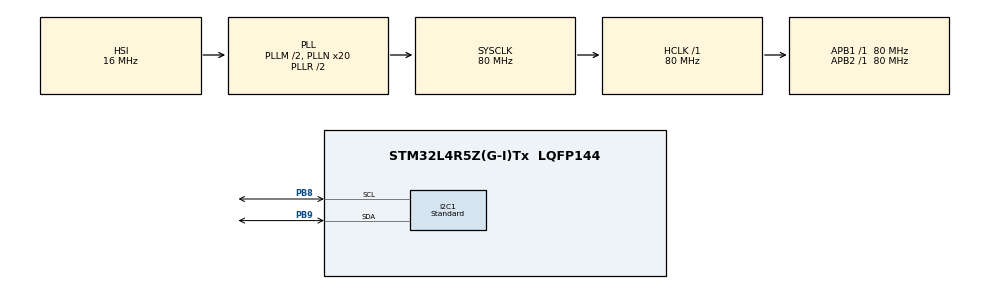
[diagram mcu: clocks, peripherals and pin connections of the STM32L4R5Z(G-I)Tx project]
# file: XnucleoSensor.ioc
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FREERTOS.Tasks01=defaultTask,0,1000,StartDefaultTask,Default,NULL,Dynamic,NULL,NULL
FREERTOS.configTOTAL_HEAP_SIZE=6000
I2C1.I2C_Speed_Mode=I2C_Standard
I2C1.Timing=0x10909CEC
Mcu.Family=STM32L4
Mcu.Name=STM32L4R5Z(G-I)Tx
Mcu.Package=LQFP144
NVIC.PriorityGroup=NVIC_PRIORITYGROUP_4
NVIC.TIM1_UP_TIM16_IRQn=true\:0\:0\:false\:false\:true\:false\:false\:true
NVIC.TimeBase=TIM1_UP_TIM16_IRQn
NVIC.TimeBaseIP=TIM1
PA13\ (JTMS/SWDIO).Mode=Serial_Wire
PA13\ (JTMS/SWDIO).Signal=SYS_JTMS-SWDIO
PA14\ (JTCK/SWCLK).Mode=Serial_Wire
PA14\ (JTCK/SWCLK).Signal=SYS_JTCK-SWCLK
PB8.Mode=I2C
PB8.Signal=I2C1_SCL
PB9.Mode=I2C
PB9.Signal=I2C1_SDA
PC14-OSC32_IN\ (PC14).Mode=LSE-External-Oscillator
PC14-OSC32_IN\ (PC14).Signal=RCC_OSC32_IN
PC15-OSC32_OUT\ (PC15).Mode=LSE-External-Oscillator
PC15-OSC32_OUT\ (PC15).Signal=RCC_OSC32_OUT
ProjectManager.HeapSize=0x200
ProjectManager.StackSize=0x400
ProjectManager.TargetToolchain=STM32CubeIDE
RCC.ADCFreq_Value=64000000
RCC.AHBFreq_Value=80000000
RCC.APB1Freq_Value=80000000
RCC.APB1TimFreq_Value=80000000
RCC.APB2Freq_Value=80000000
RCC.APB2TimFreq_Value=80000000
RCC.CortexFreq_Value=80000000
RCC.HCLKFreq_Value=80000000
RCC.HSE_VALUE=8000000
RCC.HSI48_VALUE=48000000
RCC.HSI_VALUE=16000000
RCC.MSI_VALUE=4000000
RCC.PLLM1=2
RCC.PLLN=20
RCC.PLLSourceVirtual=RCC_PLLSOURCE_HSI
RCC.SYSCLKFreq_VALUE=80000000
RCC.SYSCLKSource=RCC_SYSCLKSOURCE_PLLCLK
RCC.USBFreq_Value=64000000
RCC.VCOOutputFreq_Value=160000000
VP_FREERTOS_VS_CMSIS_V1.Mode=CMSIS_V1
VP_SYS_VS_tim1.Mode=TIM1
board=custom

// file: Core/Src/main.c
/* USER CODE BEGIN Header */
/**
  ******************************************************************************
  * @file           : main.c
  * @brief          : Main program body
  ******************************************************************************
  * @attention
  *
  * <h2><center>&copy; Copyright (c) 2021 STMicroelectronics.
  * All rights reserved.</center></h2>
  *
  * This software component is licensed by ST under BSD 3-Clause license,
  * the "License"; You may not use this file except in compliance with the
  * License. You may obtain a copy of the License at:
  *                        opensource.org/licenses/BSD-3-Clause
  *
  ******************************************************************************
  */
/* USER CODE END Header */
#include "main.h"
#include "cmsis_os.h"

I2C_HandleTypeDef hi2c1;

osThreadId defaultTaskHandle;
/* USER CODE BEGIN PV */
float temp, humm, pressure;

/* USER CODE END PV */

void SystemClock_Config(void);
static void MX_GPIO_Init(void);
static void MX_I2C1_Init(void);
void StartDefaultTask(void const * argument);

int main(void)
{

  /* MCU Configuration--------------------------------------------------------*/

  /* Reset of all peripherals, Initializes the Flash interface and the Systick. */
  HAL_Init();

  /* Configure the system clock */
  SystemClock_Config();

  /* Initialize all configured peripherals */
  MX_GPIO_Init();
  MX_I2C1_Init();
  /* USER CODE BEGIN 2 */
  uint32_t err;
  HAL_StatusTypeDef ret;

  //HAL_I2C_IsDeviceReady(hi2c, DevAddress, Trials, Timeout)
  //hi2c1->Instance->CR1;

  ret = HAL_I2C_GetState(&hi2c1);

  if(HAL_I2C_IsDeviceReady(&hi2c1, 0x95, 3, 3000)!=HAL_OK)
  {
	  err = HAL_I2C_GetError(&hi2c1);
  }

  /* USER CODE END 2 */

  /* Create the thread(s) */
  /* definition and creation of defaultTask */
  osThreadDef(defaultTask, StartDefaultTask, osPriorityNormal, 0, 1000);
  defaultTaskHandle = osThreadCreate(osThread(defaultTask), NULL);

  /* Start scheduler */
  osKernelStart();

  /* We should never get here as control is now taken by the scheduler */
  /* Infinite loop */
  while (1)
  {

  }
}

void SystemClock_Config(void)
{
  RCC_OscInitTypeDef RCC_OscInitStruct = {0};
  RCC_ClkInitTypeDef RCC_ClkInitStruct = {0};
  RCC_PeriphCLKInitTypeDef PeriphClkInit = {0};

  /** Configure the main internal regulator output voltage
  */
  if (HAL_PWREx_ControlVoltageScaling(PWR_REGULATOR_VOLTAGE_SCALE1) != HAL_OK)
  {
    Error_Handler();
  }
  /** Initializes the RCC Oscillators according to the specified parameters
  * in the RCC_OscInitTypeDef structure.
  */
  RCC_OscInitStruct.OscillatorType = RCC_OSCILLATORTYPE_HSI;
  RCC_OscInitStruct.HSIState = RCC_HSI_ON;
  RCC_OscInitStruct.HSICalibrationValue = RCC_HSICALIBRATION_DEFAULT;
  RCC_OscInitStruct.PLL.PLLState = RCC_PLL_ON;
  RCC_OscInitStruct.PLL.PLLSource = RCC_PLLSOURCE_HSI;
  RCC_OscInitStruct.PLL.PLLM = 2;
  RCC_OscInitStruct.PLL.PLLN = 20;
  RCC_OscInitStruct.PLL.PLLP = RCC_PLLP_DIV2;
  RCC_OscInitStruct.PLL.PLLQ = RCC_PLLQ_DIV2;
  RCC_OscInitStruct.PLL.PLLR = RCC_PLLR_DIV2;
  if (HAL_RCC_OscConfig(&RCC_OscInitStruct) != HAL_OK)
  {
    Error_Handler();
  }
  /** Initializes the CPU, AHB and APB buses clocks
  */
  RCC_ClkInitStruct.ClockType = RCC_CLOCKTYPE_HCLK|RCC_CLOCKTYPE_SYSCLK
                              |RCC_CLOCKTYPE_PCLK1|RCC_CLOCKTYPE_PCLK2;
  RCC_ClkInitStruct.SYSCLKSource = RCC_SYSCLKSOURCE_PLLCLK;
  RCC_ClkInitStruct.AHBCLKDivider = RCC_SYSCLK_DIV1;
  RCC_ClkInitStruct.APB1CLKDivider = RCC_HCLK_DIV1;
  RCC_ClkInitStruct.APB2CLKDivider = RCC_HCLK_DIV1;

  if (HAL_RCC_ClockConfig(&RCC_ClkInitStruct, FLASH_LATENCY_3) != HAL_OK)
  {
    Error_Handler();
  }
  PeriphClkInit.PeriphClockSelection = RCC_PERIPHCLK_I2C1;
  PeriphClkInit.I2c1ClockSelection = RCC_I2C1CLKSOURCE_PCLK1;
  if (HAL_RCCEx_PeriphCLKConfig(&PeriphClkInit) != HAL_OK)
  {
    Error_Handler();
  }
}

static void MX_I2C1_Init(void)
{

  hi2c1.Instance = I2C1;
  hi2c1.Init.Timing = 0x10909CEC;
  hi2c1.Init.OwnAddress1 = 0;
  hi2c1.Init.AddressingMode = I2C_ADDRESSINGMODE_7BIT;
  hi2c1.Init.DualAddressMode = I2C_DUALADDRESS_DISABLE;
  hi2c1.Init.OwnAddress2 = 0;
  hi2c1.Init.OwnAddress2Masks = I2C_OA2_NOMASK;
  hi2c1.Init.GeneralCallMode = I2C_GENERALCALL_DISABLE;
  hi2c1.Init.NoStretchMode = I2C_NOSTRETCH_DISABLE;
  if (HAL_I2C_Init(&hi2c1) != HAL_OK)
  {
    Error_Handler();
  }
  /** Configure Analogue filter
  */
  if (HAL_I2CEx_ConfigAnalogFilter(&hi2c1, I2C_ANALOGFILTER_ENABLE) != HAL_OK)
  {
    Error_Handler();
  }
  /** Configure Digital filter
  */
  if (HAL_I2CEx_ConfigDigitalFilter(&hi2c1, 0) != HAL_OK)
  {
    Error_Handler();
  }

}

static void MX_GPIO_Init(void)
{

  /* GPIO Ports Clock Enable */
  __HAL_RCC_GPIOC_CLK_ENABLE();
  __HAL_RCC_GPIOA_CLK_ENABLE();
  __HAL_RCC_GPIOB_CLK_ENABLE();

}

void StartDefaultTask(void const * argument)
{
	HAL_StatusTypeDef ret;
	float value_x0, value_x1, value_y0, value_y1;
	uint32_t err;
	int16_t val;
	uint8_t buf[3]={0,0,0};
	uint16_t temperature;
	uint8_t temperature_low;
	const uint8_t TMP102_ADDR = 0x95 ;

  /* USER CODE BEGIN 5 */
  /* Infinite loop */
  for(;;)
  {
	  // temperature
	  	buf[0] = 0x0; // hi bit
	  	ret = HAL_I2C_Master_Transmit(&hi2c1, TMP102_ADDR, buf, 1, 3000);
	  	ret = HAL_I2C_Master_Receive(&hi2c1, TMP102_ADDR, (uint8_t*)&temperature, 1, 3000);

	  	buf[0] = 0x2; // lo bit
	  	ret = HAL_I2C_Master_Transmit(&hi2c1, TMP102_ADDR, buf, 1, 3000);
	  	ret = HAL_I2C_Master_Receive(&hi2c1, TMP102_ADDR, &temperature_low, 1, 3000);

	  	temperature  = (temperature << 8) + temperature_low;
	  	temp = ((float)temperature) / 256.0f;

	  	// humidity
	  	ret = HAL_I2C_Mem_Read(&hi2c1, 0xBF, 0x36 | 0x80U, I2C_MEMADD_SIZE_8BIT, buf, 2, 3000);
	  	value_x0 = (int16_t)((buf[1] * 256) + buf[0]) * 1.0f;

	  	ret = HAL_I2C_Mem_Read(&hi2c1, 0xBF, 0x30 | 0x80U, I2C_MEMADD_SIZE_8BIT, buf, 1, 3000);
	  	value_y0 = buf[0] / 2.0f;

	  	ret = HAL_I2C_Mem_Read(&hi2c1, 0xBF, 0x3A | 0x80U, I2C_MEMADD_SIZE_8BIT, buf, 2, 3000);
	  	value_x1 = (int16_t)((buf[1] * 256) + buf[0]) * 1.0f;

	  	ret = HAL_I2C_Mem_Read(&hi2c1, 0xBF, 0x31 | 0x80U, I2C_MEMADD_SIZE_8BIT, buf, 1, 3000);
	  	value_y1 = buf[0] / 2.0f;

	  	ret = HAL_I2C_Mem_Read(&hi2c1, 0xBF, 0x28 | 0x80, I2C_MEMADD_SIZE_8BIT, buf, 2, 3000);
	  	val = (int16_t)buf[1];
	  	val = (val * 256) +  (int16_t)buf[0];
	  	// interpolation
	  	humm = (((value_y1 - value_y0) * val) + ((value_x1 * value_y0) - (value_x0 * value_y1))) / (value_x1 - value_x0);

	  	if (humm < 0.0f)
	  		humm = 0.0f;
	  	if (humm > 100.0f)
	  		humm = 100.0f;

	  	// presure
	  	ret = HAL_I2C_Mem_Read(&hi2c1, 0xBB, 0x28, I2C_MEMADD_SIZE_8BIT, buf, 3, 3000);

	  	uint32_t buff = buf[2];
	  	buff = (buff * 256) + buf[1];
	  	buff = (buff * 256) + buf[0];
	  	buff *= 256;
	  	pressure =  (float) buff / 1048576.0f ;

	  	osDelay(5000);
  }
  /* USER CODE END 5 */
}

 /**
  * @brief  Period elapsed callback in non blocking mode
  * @note   This function is called  when TIM1 interrupt took place, inside
  * HAL_TIM_IRQHandler(). It makes a direct call to HAL_IncTick() to increment
  * a global variable "uwTick" used as application time base.
  * @param  htim : TIM handle
  * @retval None
  */
void HAL_TIM_PeriodElapsedCallback(TIM_HandleTypeDef *htim)
{
  if (htim->Instance == TIM1) {
    HAL_IncTick();
  }
}

void Error_Handler(void)
{
  __disable_irq();
  while (1)
  {
  }
}

/************************ (C) COPYRIGHT STMicroelectronics *****END OF FILE****/
